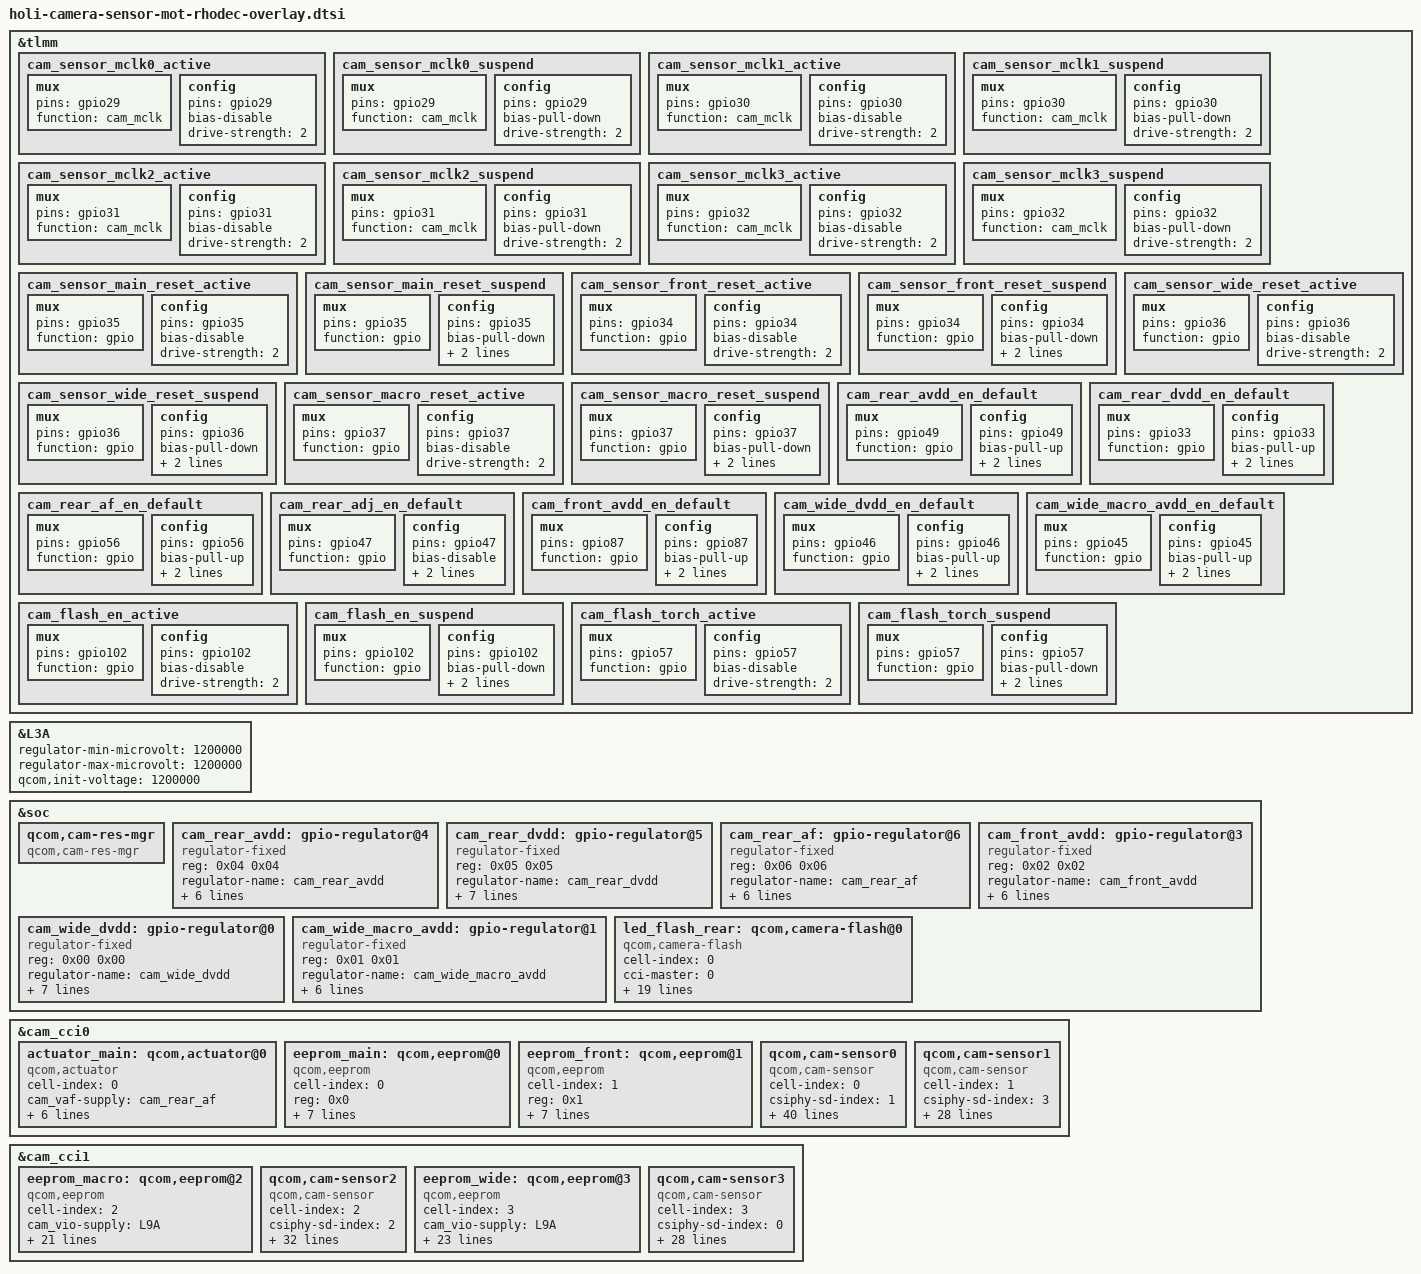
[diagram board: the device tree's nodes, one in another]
#include <dt-bindings/clock/qcom,gcc-holi.h>
#include <dt-bindings/msm/msm-camera.h>

&tlmm {
	cam_sensor_mclk0_active: cam_sensor_mclk0_active {
		mux {
			pins = "gpio29";
			function = "cam_mclk";
		};

		config {
			pins = "gpio29";
			bias-disable; /* No PULL */
			drive-strength = <2>; /* 2 MA */
		};
	};

	cam_sensor_mclk0_suspend: cam_sensor_mclk0_suspend {
		mux {
			pins = "gpio29";
			function = "cam_mclk";
		};

		config {
			pins = "gpio29";
			bias-pull-down; /* PULL DOWN */
			drive-strength = <2>; /* 2 MA */
		};
	};

	cam_sensor_mclk1_active: cam_sensor_mclk1_active {
		mux {
			pins = "gpio30";
			function = "cam_mclk";
		};

		config {
			pins = "gpio30";
			bias-disable; /* No PULL */
			drive-strength = <2>;
		};
	};

	cam_sensor_mclk1_suspend: cam_sensor_mclk1_suspend {
		mux {
			pins = "gpio30";
			function = "cam_mclk";
		};

		config {
			pins = "gpio30";
			bias-pull-down; /* PULL DOWN */
			drive-strength = <2>;
		};
	};

	cam_sensor_mclk2_active: cam_sensor_mclk2_active {
		mux {
			pins = "gpio31";
			function = "cam_mclk";
		};

		config {
			pins = "gpio31";
			bias-disable; /* No PULL */
			drive-strength = <2>;
		};
	};

	cam_sensor_mclk2_suspend: cam_sensor_mclk2_suspend {
		mux {
			pins = "gpio31";
			function = "cam_mclk";
		};

		config {
			pins = "gpio31";
			bias-pull-down; /* PULL DOWN */
			drive-strength = <2>;
		};
	};

	cam_sensor_mclk3_active: cam_sensor_mclk3_active {
		mux {
			pins = "gpio32";
			function = "cam_mclk";
		};

		config {
			pins = "gpio32";
			bias-disable; /* No PULL */
			drive-strength = <2>; /* 2 MA */
		};
	};

	cam_sensor_mclk3_suspend: cam_sensor_mclk3_suspend {
		mux {
			pins = "gpio32";
			function = "cam_mclk";
		};

		config {
			pins = "gpio32";
			bias-pull-down; /* PULL DOWN */
			drive-strength = <2>; /* 2 MA */
		};
	};

	cam_sensor_main_reset_active: cam_sensor_main_reset_active {
		mux {
			pins = "gpio35";
			function = "gpio";
		};

		config {
			pins = "gpio35";
			bias-disable; /* No PULL */
			drive-strength = <2>; /* 2 MA */
		};
	};

	cam_sensor_main_reset_suspend: cam_sensor_main_reset_suspend {
		mux {
			pins = "gpio35";
			function = "gpio";
		};

		config {
			pins = "gpio35";
			bias-pull-down; /* PULL DOWN */
			drive-strength = <2>; /* 2 MA */
			output-low;
		};
	};

	cam_sensor_front_reset_active: cam_sensor_front_reset_active {
		mux {
			pins = "gpio34";
			function = "gpio";
		};

		config {
			pins = "gpio34";
			bias-disable; /* No PULL */
			drive-strength = <2>; /* 2 MA */
		};
	};

	cam_sensor_front_reset_suspend: cam_sensor_front_reset_suspend {
		mux {
			pins = "gpio34";
			function = "gpio";
		};

		config {
			pins = "gpio34";
			bias-pull-down; /* PULL DOWN */
			drive-strength = <2>; /* 2 MA */
			output-low;
		};
	};

	cam_sensor_wide_reset_active: cam_sensor_wide_reset_active {
		mux {
			pins = "gpio36";
			function = "gpio";
		};

		config {
			pins = "gpio36";
			bias-disable; /* No PULL */
			drive-strength = <2>; /* 2 MA */
		};
	};

	cam_sensor_wide_reset_suspend: cam_sensor_wide_reset_suspend {
		mux {
			pins = "gpio36";
			function = "gpio";
		};

		config {
			pins = "gpio36";
			bias-pull-down; /* PULL DOWN */
			drive-strength = <2>; /* 2 MA */
			output-low;
		};
	};

	cam_sensor_macro_reset_active: cam_sensor_macro_reset_active {
		mux {
			pins = "gpio37";
			function = "gpio";
		};

		config {
			pins = "gpio37";
			bias-disable; /* No PULL */
			drive-strength = <2>; /* 2 MA */
		};
	};

	cam_sensor_macro_reset_suspend: cam_sensor_macro_reset_suspend {
		mux {
			pins = "gpio37";
			function = "gpio";
		};

		config {
			pins = "gpio37";
			bias-pull-down; /* PULL DOWN */
			drive-strength = <2>; /* 2 MA */
			output-low;
		};
	};

	cam_rear_avdd_en_default: cam_rear_avdd_en_default {
		mux {
			pins = "gpio49";
			function = "gpio";
		};

		config {
			pins = "gpio49";
			bias-pull-up; /* PULL UP */
			drive-strength = <2>; /* 2 MA */
			output-high;
		};
	};
	cam_rear_dvdd_en_default: cam_rear_dvdd_en_default {
		mux {
			pins = "gpio33";
			function = "gpio";
		};

		config {
			pins = "gpio33";
			bias-pull-up; /* PULL UP */
			drive-strength = <2>; /* 2 MA */
			output-high;
		};
	};
	cam_rear_af_en_default: cam_rear_af_en_default {
		mux {
			pins = "gpio56";
			function = "gpio";
        };

		config {
			pins = "gpio56";
			bias-pull-up; /* PULL UP */
			drive-strength = <2>; /* 2 MA */
			output-high;
		};
	};
	cam_rear_adj_en_default: cam_rear_adj_en_default {
		mux {
			pins = "gpio47";
			function = "gpio";
		};

		config {
			pins = "gpio47";
			bias-disable; /* NO PULL */
			drive-strength = <2>; /* 2 MA */
			input-high;
		};
	};

	cam_front_avdd_en_default: cam_front_avdd_en_default {
		mux {
			pins = "gpio87";
			function = "gpio";
		};

		config {
			pins = "gpio87";
			bias-pull-up; /* PULL UP */
			drive-strength = <2>; /* 2 MA */
			output-high;
		};
	};

	cam_wide_dvdd_en_default: cam_wide_dvdd_en_default {
		mux {
			pins = "gpio46";
			function = "gpio";
		};

		config {
			pins = "gpio46";
			bias-pull-up; /* PULL UP */
			drive-strength = <2>; /* 2 MA */
			output-high;
		};
	};

	cam_wide_macro_avdd_en_default: cam_wide_macro_avdd_en_default {
		mux {
			pins = "gpio45";
			function = "gpio";
		};

		config {
			pins = "gpio45";
			bias-pull-up; /* PULL UP */
			drive-strength = <2>; /* 2 MA */
			output-high;
		};
	};
	cam_flash_en_active: cam_flash_en_active {
		mux {
			pins = "gpio102";
			function = "gpio";
		};

		config {
			pins = "gpio102";
			bias-disable; /* No PULL */
			drive-strength = <2>; /* 2 MA */
		};
	};
	cam_flash_en_suspend: cam_flash_en_suspend {
		mux {
			pins = "gpio102";
			function = "gpio";
		};

		config {
			pins = "gpio102";
			bias-pull-down; /* PULL DOWN */
			drive-strength = <2>; /* 2 MA */
			output-low;
		};
	};
	cam_flash_torch_active: cam_flash_torch_active {
		/* AFVDD */
		mux {
			pins = "gpio57";
			function = "gpio";
		};

		config {
			pins = "gpio57";
			bias-disable; /* No PULL */
			drive-strength = <2>; /* 2 MA */
		};
	};
	cam_flash_torch_suspend: cam_flash_torch_suspend {
		/* AFVDD */
		mux {
			pins = "gpio57";
			function = "gpio";
		};

		config {
			pins = "gpio57";
			bias-pull-down; /* PULL DOWN */
			drive-strength = <2>; /* 2 MA */
			output-low;
		};
	};
};

&L3A{
	regulator-min-microvolt = <1200000>;
	regulator-max-microvolt = <1200000>;
	qcom,init-voltage = <1200000>;
	status = "okay";
};

&soc {
	qcom,cam-res-mgr {
		compatible = "qcom,cam-res-mgr";
		status = "ok";
	};

	cam_rear_avdd: gpio-regulator@4{
		compatible = "regulator-fixed";
		reg = <0x04 0x04>;
		regulator-name = "cam_rear_avdd";
		regulator-min-microvolt = <2800000>;
		regulator-max-microvolt = <2800000>;
		regulator-enable-ramp-delay = <233>;
		enable-active-high;
		gpio = <&tlmm 49 0>;
		pinctrl-names = "default";
		pinctrl-0 = <&cam_rear_avdd_en_default>;
	};
	cam_rear_dvdd: gpio-regulator@5{
		compatible = "regulator-fixed";
		reg = <0x05 0x05>;
		regulator-name = "cam_rear_dvdd";
		regulator-min-microvolt = <1050000>;
		regulator-max-microvolt = <1050000>;
		regulator-enable-ramp-delay = <233>;
		enable-active-high;
		gpio = <&tlmm 33 0>;
		pinctrl-names = "default";
		pinctrl-0 = <&cam_rear_dvdd_en_default>;
		vin-supply = <&S6A>;
	};
	cam_rear_af: gpio-regulator@6{
		compatible = "regulator-fixed";
		reg = <0x06 0x06>;
		regulator-name = "cam_rear_af";
		regulator-min-microvolt = <2800000>;
		regulator-max-microvolt = <2800000>;
		regulator-enable-ramp-delay = <233>;
		enable-active-high;
		gpio = <&tlmm 56 0>;
		pinctrl-names = "default";
		pinctrl-0 = <&cam_rear_af_en_default>;
	};
	cam_front_avdd: gpio-regulator@3{
		compatible = "regulator-fixed";
		reg = <0x02 0x02>;
		regulator-name = "cam_front_avdd";
		regulator-min-microvolt = <2800000>;
		regulator-max-microvolt = <2800000>;
		regulator-enable-ramp-delay = <233>;
		enable-active-high;
		gpio = <&tlmm 87 0>;
		pinctrl-names = "default";
		pinctrl-0 = <&cam_front_avdd_en_default>;
		/*vin-supply = <&BOB>;*/
	};

	cam_wide_dvdd: gpio-regulator@0{
		compatible = "regulator-fixed";
		reg = <0x00 0x00>;
		regulator-name = "cam_wide_dvdd";
		regulator-min-microvolt = <1200000>;
		regulator-max-microvolt = <1200000>;
		regulator-enable-ramp-delay = <233>;
		enable-active-high;
		gpio = <&tlmm 46 0>;
		pinctrl-names = "default";
		pinctrl-0 = <&cam_wide_dvdd_en_default>;
		vin-supply = <&S6A>;
	};

	cam_wide_macro_avdd: gpio-regulator@1{
		compatible = "regulator-fixed";
		reg = <0x01 0x01>;
		regulator-name = "cam_wide_macro_avdd";
		regulator-min-microvolt = <2800000>;
		regulator-max-microvolt = <2800000>;
		regulator-enable-ramp-delay = <233>;
		enable-active-high;
		gpio = <&tlmm 45 0>;
		pinctrl-names = "default";
		pinctrl-0 = <&cam_wide_macro_avdd_en_default>;
		/*vin-supply = <&BOB>;*/
	};

	led_flash_rear: qcom,camera-flash@0 {
		cell-index = <0>;
		compatible = "qcom,camera-flash";
		cci-master = <0>;
		flash-type = <CAM_FLASH_TYPE_I2C>;
		cam_vio-supply = <&L9A>;
		regulator-names = "cam_vio";
		rgltr-cntrl-support;
		rgltr-min-voltage = <1800000>;
		rgltr-max-voltage = <1800000>;
		rgltr-load-current = <120000>;
		gpio-no-mux = <0>;
		pinctrl-names = "cam_default","cam_suspend";
		pinctrl-0 = <&cam_flash_en_active &cam_flash_torch_active>;
		pinctrl-1 = <&cam_flash_en_suspend &cam_flash_torch_suspend>;
		gpios = <&tlmm 102 0>,
			<&tlmm 57 0>;
		gpio-custom1 = <0>;
		gpio-custom2 = <1>;
		gpio-req-tbl-num = <0 1>;
		gpio-req-tbl-flags = <0 0>;
		gpio-req-tbl-label = "SENSOR_CUSTOM_GPIO1",
				"SENSOR_CUSTOM_GPIO2";
 		status = "ok";
	};
};

&cam_cci0 {
	actuator_main: qcom,actuator@0 {
		cell-index = <0>;
		compatible = "qcom,actuator";
		cam_vaf-supply = <&cam_rear_af>;
		regulator-names = "cam_vaf";
		rgltr-cntrl-support;
		rgltr-min-voltage = <2800000>;
		rgltr-max-voltage = <2800000>;
		rgltr-load-current = <100000>;
		cci-master = <1>;
		status = "ok";
	};

	eeprom_main: qcom,eeprom@0 {
		cell-index = <0>;
		reg = <0x0>;
		compatible = "qcom,eeprom";
		cam_vio-supply = <&L9A>;
		regulator-names = "cam_vio";
		rgltr-cntrl-support;
		rgltr-min-voltage = <1800000>;
		rgltr-max-voltage = <1800000>;
		rgltr-load-current = <120000>;
		cci-master = <1>;
		status = "ok";
	};

	eeprom_front: qcom,eeprom@1 {
		cell-index = <1>;
		reg = <0x1>;
		compatible = "qcom,eeprom";
		cam_vio-supply = <&L9A>;
		regulator-names = "cam_vio";
		rgltr-cntrl-support;
		rgltr-min-voltage = <1800000>;
		rgltr-max-voltage = <1800000>;
		rgltr-load-current = <3000>;
		cci-master = <0>;
		status = "ok";
	};

	qcom,cam-sensor0 {
		cell-index = <0>;
		compatible = "qcom,cam-sensor";
		csiphy-sd-index = <1>;
		sensor-position-roll = <90>;
		sensor-position-pitch = <0>;
		sensor-position-yaw = <180>;
		actuator-src = <&actuator_main>;
		eeprom-src = <&eeprom_main>;
		led-flash-src = <&led_flash_rear>;
		cam_vio-supply = <&L9A>;
		cam_vana-supply = <&cam_rear_avdd>;
		cam_vdig-supply = <&cam_rear_dvdd>;
		cam_clk-supply = <&gcc_camss_top_gdsc>;
		cam_vaf-supply = <&cam_rear_af>;
		regulator-names = "cam_vio", "cam_vana", "cam_vdig",
			"cam_clk", "cam_vaf";
		rgltr-cntrl-support;
		rgltr-min-voltage = <1800000 2800000 1050000 0 2800000>;
		rgltr-max-voltage = <1800000 2800000 1050000 0 2800000>;
		rgltr-load-current = <120000 80000 1200000 0 100000>;
		gpio-no-mux = <0>;
		pinctrl-names = "cam_default", "cam_suspend";
		pinctrl-0 = <&cam_sensor_mclk0_active
				&cam_sensor_main_reset_active
				&cam_flash_en_active
				&cam_rear_adj_en_default>;
		pinctrl-1 = <&cam_sensor_mclk0_suspend
				&cam_sensor_main_reset_suspend
				&cam_flash_en_suspend>;
		gpios = <&tlmm 29 0>,
			<&tlmm 35 0>,
			<&tlmm 102 0>,
			<&tlmm 47 0>;
		gpio-reset = <1>;
		gpio-custom2 = <2>;
		gpio-custom1 = <3>;
		gpio-req-tbl-num = <0 1 2 3>;
		gpio-req-tbl-flags = <1 0 0 0>;
		gpio-req-tbl-label = "CAMIF_MCLK0",
					"CAM_RESET0",
					"CAM_FLASH_EN",
					"CAM_DVDD_SEL0";
		cci-master = <1>;
		status = "ok";
		need-change-cci-master;
		clocks = <&gcc GCC_CAMSS_MCLK0_CLK>;
		clock-names = "cam_clk";
		clock-cntl-level = "turbo";
		clock-rates = <24000000>;
	};

	qcom,cam-sensor1 {
		cell-index = <1>;
		compatible = "qcom,cam-sensor";
		csiphy-sd-index = <3>;
		sensor-position-roll = <270>;
		sensor-position-pitch = <0>;
		sensor-position-yaw = <0>;
		eeprom-src = <&eeprom_front>;
		cam_vio-supply = <&L9A>;
		cam_vana-supply = <&cam_front_avdd>;
		cam_vdig-supply = <&L3A>;
		cam_clk-supply = <&gcc_camss_top_gdsc>;
		regulator-names = "cam_vio", "cam_vana", "cam_vdig",
			"cam_clk";
		rgltr-cntrl-support;
		rgltr-min-voltage = <1800000 2800000 1200000 0>;
		rgltr-max-voltage = <1800000 2800000 1200000 0>;
		rgltr-load-current = <120000 80000 1200000 0>;
		gpio-no-mux = <0>;
		pinctrl-names = "cam_default", "cam_suspend";
		pinctrl-0 = <&cam_sensor_mclk2_active
				&cam_sensor_front_reset_active>;
		pinctrl-1 = <&cam_sensor_mclk2_suspend
				&cam_sensor_front_reset_suspend>;
		gpios = <&tlmm 31 0>,
			<&tlmm 34 0>;
		gpio-reset = <1>;
		gpio-req-tbl-num = <0 1>;
		gpio-req-tbl-flags = <1 0>;
		gpio-req-tbl-label = "CAMIF_MCLK2",
					"CAM_RESET0";
		cci-master = <0>;
		status = "ok";
		clocks = <&gcc GCC_CAMSS_MCLK2_CLK>;
		clock-names = "cam_clk";
		clock-cntl-level = "turbo";
		clock-rates = <24000000>;
	};
};

&cam_cci1 {
	eeprom_macro: qcom,eeprom@2 {
		cell-index = <2>;
		compatible = "qcom,eeprom";
		cam_vio-supply = <&L9A>;
		cam_vana-supply = <&cam_wide_macro_avdd>;
		cam_clk-supply = <&gcc_camss_top_gdsc>;
		regulator-names = "cam_vio", "cam_vana",
			"cam_clk";
		rgltr-cntrl-support;
		rgltr-min-voltage = <1800000 2800000 0>;
		rgltr-max-voltage = <1800000 2800000 0>;
		rgltr-load-current = <120000 80000 0>;
		gpio-no-mux = <0>;
		pinctrl-names = "cam_default", "cam_suspend";
		pinctrl-0 = <&cam_sensor_mclk1_active
				&cam_sensor_wide_reset_active>;
		pinctrl-1 = <&cam_sensor_mclk1_suspend
				&cam_sensor_wide_reset_suspend>;
		gpios = <&tlmm 30 0>,
			<&tlmm 37 0>;
		gpio-reset = <1>;
		gpio-req-tbl-num = <0 1>;
		gpio-req-tbl-flags = <1 0>;
		gpio-req-tbl-label = "CAMIF_MCLK1",
					"CAM_RESET2";
		cci-master = <0>;
		status = "ok";
		clocks = <&gcc GCC_CAMSS_MCLK1_CLK>;
		clock-names = "cam_clk";
		clock-cntl-level = "turbo";
		clock-rates = <24000000>;
	};
	qcom,cam-sensor2 {
		cell-index = <2>;
		compatible = "qcom,cam-sensor";
		csiphy-sd-index = <2>;
		sensor-position-roll = <90>;
		sensor-position-pitch = <0>;
		sensor-position-yaw = <180>;
		eeprom-src = <&eeprom_macro>;
		led-flash-src = <&led_flash_rear>;
		cam_vio-supply = <&L9A>;
		cam_vana-supply = <&cam_wide_macro_avdd>;
		cam_clk-supply = <&gcc_camss_top_gdsc>;
		regulator-names = "cam_vio","cam_vana", "cam_clk";
		rgltr-cntrl-support;
		rgltr-min-voltage = <1800000 2800000 0>;
		rgltr-max-voltage = <1800000 2800000 0>;
		rgltr-load-current = <120000 120000 0>;
		gpio-no-mux = <0>;
		pinctrl-names = "cam_default", "cam_suspend";
		pinctrl-0 = <&cam_sensor_mclk1_active
				&cam_sensor_macro_reset_active
				&cam_flash_en_active>;
		pinctrl-1 = <&cam_sensor_mclk1_suspend
				&cam_sensor_macro_reset_suspend
				&cam_flash_en_suspend>;
		gpios = <&tlmm 30 0>,
			<&tlmm 37 0>,
			<&tlmm 102 0>;
		gpio-reset = <1>;
		gpio-custom2 = <2>;
		gpio-req-tbl-num = <0 1 2>;
		gpio-req-tbl-flags = <1 0 0>;
		gpio-req-tbl-label = "CAMIF_MCLK1",
					"CAM_RESET2",
					"CAM_FLASH_EN";
		cci-master = <0>;
		status = "ok";
		need-change-cci-master;
		clocks = <&gcc GCC_CAMSS_MCLK1_CLK>;
		clock-names = "cam_clk";
		clock-cntl-level = "turbo";
		clock-rates = <24000000>;
	};
	eeprom_wide: qcom,eeprom@3 {
		cell-index = <3>;
		compatible = "qcom,eeprom";
		cam_vio-supply = <&L9A>;
		cam_vana-supply = <&cam_wide_macro_avdd>;
		cam_vdig-supply = <&cam_wide_dvdd>;
		cam_clk-supply = <&gcc_camss_top_gdsc>;
		regulator-names = "cam_vio", "cam_vana", "cam_vdig",
			"cam_clk";
		rgltr-cntrl-support;
		rgltr-min-voltage = <1800000 2800000 1200000 0>;
		rgltr-max-voltage = <1800000 2800000 1200000 0>;
		rgltr-load-current = <120000 80000 1200000 0>;
		gpio-no-mux = <0>;
		pinctrl-names = "cam_default", "cam_suspend";
		pinctrl-0 = <&cam_sensor_mclk3_active
				&cam_sensor_wide_reset_active>;
		pinctrl-1 = <&cam_sensor_mclk3_suspend
				&cam_sensor_wide_reset_suspend>;
		gpios = <&tlmm 32 0>,
			<&tlmm 36 0>;
		gpio-reset = <1>;
		gpio-req-tbl-num = <0 1>;
		gpio-req-tbl-flags = <1 0>;
		gpio-req-tbl-label = "CAMIF_MCLK3",
					"CAM_RESET3";
		cci-master = <0>;
		status = "ok";
		clocks = <&gcc GCC_CAMSS_MCLK3_CLK>;
		clock-names = "cam_clk";
		clock-cntl-level = "turbo";
		clock-rates = <24000000>;
	};
	qcom,cam-sensor3 {
		cell-index = <3>;
		compatible = "qcom,cam-sensor";
		csiphy-sd-index = <0>;
		sensor-position-roll = <90>;
		sensor-position-pitch = <0>;
		sensor-position-yaw = <180>;
		eeprom-src = <&eeprom_wide>;
		cam_vio-supply = <&L9A>;
		cam_vana-supply = <&cam_wide_macro_avdd>;
		cam_vdig-supply = <&cam_wide_dvdd>;
		cam_clk-supply = <&gcc_camss_top_gdsc>;
		regulator-names = "cam_vio", "cam_vana", "cam_vdig",
			"cam_clk";
		rgltr-cntrl-support;
		rgltr-min-voltage = <1800000 2800000 1200000 0>;
		rgltr-max-voltage = <1800000 2800000 1200000 0>;
		rgltr-load-current = <120000 80000 1200000 0>;
		gpio-no-mux = <0>;
		pinctrl-names = "cam_default", "cam_suspend";
		pinctrl-0 = <&cam_sensor_mclk3_active
				&cam_sensor_wide_reset_active>;
		pinctrl-1 = <&cam_sensor_mclk3_suspend
				&cam_sensor_wide_reset_suspend>;
		gpios = <&tlmm 32 0>,
			<&tlmm 36 0>;
		gpio-reset = <1>;
		gpio-req-tbl-num = <0 1>;
		gpio-req-tbl-flags = <1 0>;
		gpio-req-tbl-label = "CAMIF_MCLK3",
					"CAM_RESET3";
		cci-master = <0>;
		status = "ok";
		clocks = <&gcc GCC_CAMSS_MCLK3_CLK>;
		clock-names = "cam_clk";
		clock-cntl-level = "turbo";
		clock-rates = <24000000>;
	};
};
